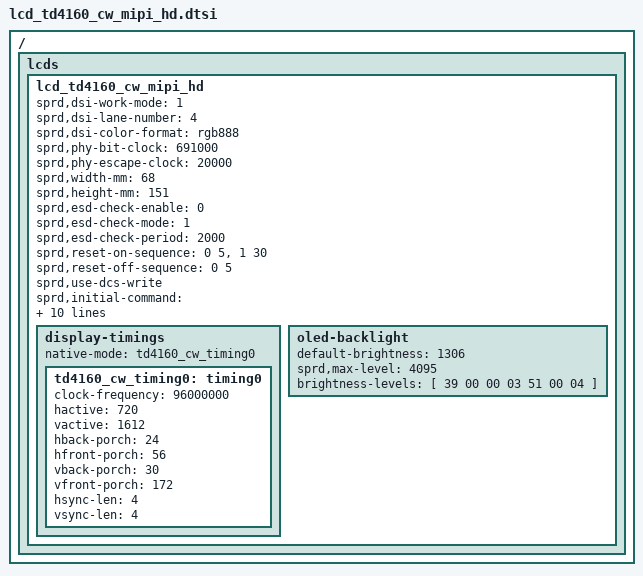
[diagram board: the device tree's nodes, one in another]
/*
 * R61350 Truly LCD config dtsi file for spreadtrum
 *
 * Copyright (C) 2018, Spreadtrum Communications Inc.
 *
 * SPDX-License-Identifier: (GPL-2.0+ OR MIT)
 */

/ {
	fragment {
		target-path = "/";
		__overlay__ {
			lcds {
				lcd_td4160_cw_mipi_hd: lcd_td4160_cw_mipi_hd {

					sprd,dsi-work-mode = <1>; /* video burst mode*/
					sprd,dsi-lane-number = <4>;
					sprd,dsi-color-format = "rgb888";

					sprd,phy-bit-clock = <691000>;	/* kbps */
					sprd,phy-escape-clock = <20000>;/* kHz */

					sprd,width-mm = <68>;
					sprd,height-mm = <151>;

					sprd,esd-check-enable = <0>;
					sprd,esd-check-mode = <1>;
					sprd,esd-check-period = <2000>;
					/* sprd,esd-check-register = <0x0A>; */
					/* sprd,esd-check-value = <0x9C>; */

					sprd,reset-on-sequence = <0 5>, <1 30>;
					sprd,reset-off-sequence = <0 5>;

					sprd,use-dcs-write;
					sprd,initial-command = [
		29 00 00 02 B0 00
		29 00 00 02 D6 00
		29 00 00 07 B6 30 62 00 86 C3 03 
		29 00 00 05 B7 31 00 00 00 
		29 00 00 07 B8 02 4A 06 00 04 5A 
		29 00 00 07 B9 02 4A 18 00 09 B4 
		29 00 00 07 BA 20 00 00 00 00 00 
		29 00 00 04 BB 00 B4 A0 
		29 00 00 04 BC 00 B4 A0 
		29 00 00 04 BD 00 B4 A0 
		29 00 00 0E BE 07 00 00 00 00 00 00 00 00 00 00 00 00 
		29 00 00 19 C0 00 80 18 06 4C 00 16 08 68 00 70 00 00 00 00 00 00 00 00 00 00 00 00 00 
		29 00 00 28 C1 30 41 50 FA 01 00 00 10 00 00 00 00 40 0F 00 00 00 00 00 00 00 00 00 00 00 00 00 00 00 00 00 00 00 00 00 00 00 00 00 
		29 00 00 F5 C2 00 00 50 14 06 10 0E 00 00 00 00 50 12 06 10 0A 00 00 00 00 50 12 06 06 69 00 00 00 00 00 00 00 00 00 00 00 00 00 00 00 00 00 05 D0 56 0C 0C 06 00 C1 00 B0 01 03 00 41 00 00 00 00 00 11 00 00 00 00 00 00 00 00 00 00 00 00 00 00 00 00 00 00 00 00 00 00 00 00 00 00 00 00 00 00 00 11 00 00 00 00 00 00 00 00 00 00 00 00 00 00 00 00 00 00 00 00 00 00 00 00 00 00 00 00 00 00 00 11 00 00 00 00 00 00 00 00 00 00 00 00 00 00 00 00 00 00 00 00 00 00 00 00 00 00 00 00 00 00 00 11 00 00 00 00 00 00 00 00 00 00 00 00 00 00 00 00 00 00 00 00 00 00 00 00 00 00 00 00 00 00 00 00 00 00 00 00 00 00 00 10 00 00 00 00 00 00 00 00 00 00 00 00 00 00 00 02 00 00 00 00 00 00 00 00 00 00 02 00 00 00 00 00 00 00 00 00 00 00 00 00 00 00 00 00 00 00 
		29 00 00 6A C3 00 00 50 01 67 10 05 00 00 00 20 00 04 E0 00 41 64 C0 02 00 00 00 20 00 00 00 00 00 00 00 00 00 00 00 20 00 00 00 00 00 00 00 00 00 00 00 20 00 00 00 00 08 00 00 00 00 00 00 00 00 00 00 00 00 00 00 00 00 00 00 00 00 00 00 00 00 00 00 00 00 00 00 00 00 00 00 00 00 00 00 00 00 00 00 00 00 00 00 00 00 00 00 00 00 00 
		29 00 00 55 C4 00 5F 5F 0C 5D 04 06 08 01 14 14 16 16 18 18 1A 1A 1C 1C 1E 1E 5F 00 00 5F 1D 1D 1B 1B 19 19 17 17 15 15 13 13 01 07 05 03 5D 0B 5F 5F 00 00 00 00 00 00 00 FF 0F FF 0F 00 00 00 00 00 00 00 00 00 00 00 00 00 33 33 00 00 55 55 55 55 55 41 55 55 55 55 55 
		29 00 00 06 C5 08 00 00 00 00 
		29 00 00 4D C6 00 00 00 00 01 22 04 22 01 00 53 00 00 00 01 00 53 00 01 05 01 0B 01 35 FF 8F 06 15 01 C0 07 00 00 00 00 00 00 00 00 00 00 00 00 00 00 00 00 00 00 00 00 00 00 20 20 00 00 00 C0 11 00 00 00 10 10 00 00 00 01 00 50 00 33 03 00 00 
		29 00 00 1F CB 02 D0 01 80 00 00 00 00 00 00 00 00 00 00 00 00 00 00 00 00 00 00 40 70 00 00 00 00 00 FF 
		29 00 00 19 CE 16 40 60 78 87 94 9E AB B8 C4 CD D6 DE E5 EC F3 FF 07 0F 00 00 00 04 8C 
		29 00 00 02 CF 00 
		29 00 00 15 D0 C1 50 81 66 09 90 00 CC 92 9F 11 1E 06 7E 09 08 CC 1B F0 06 
		29 00 00 26 D1 D0 D0 1B 33 33 17 07 BB 22 52 22 52 00 3B 77 07 3B 30 06 72 33 13 00 D7 0C 22 02 00 18 70 18 77 11 11 11 20 20
		29 00 00 04 D2 00 00 00 
		29 00 00 9A D3 00 00 00 00 00 00 00 00 00 FF F7 FF FF F7 FF FF F7 FF FF F7 FF FF F7 FF FF F7 FF FF F7 FF FF F7 FF FF F7 FF FF F7 FF FF F7 FF FF F7 FF FF F7 FF FF F7 FF FF F7 FF FF F7 FF FF F7 FF FF F7 FF FF F7 FF FF F7 FF FF F7 FF FF F7 FF FF F7 FF FF F7 FF FF F7 FF FF F7 FF FF F7 FF FF F7 FF FF F7 FF FF F7 FF FF F7 FF FF F7 FF FF F7 FF FF F7 FF FF F7 FF FF F7 FF FF F7 FF FF F7 FF FF F7 FF FF F7 FF FF F7 FF FF F7 FF FF F7 FF FF F7 FF FF F7 FF FF F7 FF FF F7 FF FF F7 FF 
		29 00 00 18 D4 00 00 00 00 00 00 00 00 00 20 00 00 00 00 20 00 00 00 00 00 00 00 00 
		29 00 00 2F D7 01 00 12 12 00 54 01 04 00 54 01 04 03 83 80 85 85 85 87 84 45 86 87 80 88 86 89 83 83 87 84 88 8A 0C 0B 0A 0A 0A 07 07 06 06 00 08 0A 0A 
		29 00 00 17 D8 40 99 26 ED 16 6C 16 6C 16 6C 00 14 00 14 00 14 01 0C 00 00 01 00 
		29 00 00 29 D9 00 02 7F 00 00 00 00 00 00 00 00 00 00 00 00 C0 00 00 00 00 00 00 00 00 00 00 00 00 00 00 00 00 00 00 00 00 00 00 00 00 
		29 00 00 05 DD 30 06 23 65 
		29 00 00 0F DE 00 00 00 0F FF 00 00 00 00 10 00 00 00 00 
		29 00 00 09 E6 00 00 00 00 00 00 00 00 
		29 00 00 24 EA 02 0E 0E 06 80 07 40 74 00 00 00 03 33 07 07 00 54 00 54 00 54 01 28 01 28 00 54 00 54 00 54 00 08 02 00 
		29 00 00 09 EB 08 30 83 0B 41 01 08 00 
		29 00 00 18 EC 05 F0 01 70 6B 07 40 74 00 00 00 02 2A 00 00 00 00 00 00 00 00 00 00 
		29 00 00 22 ED 01 02 00 00 00 00 00 00 67 C6 FE 00 00 00 00 00 00 00 00 00 00 00 02 B0 00 00 00 00 00 00 C0 10 00 
		29 00 00 7A EE 05 00 01 00 C0 57 00 C0 57 00 C0 57 00 00 03 00 C0 57 00 00 00 00 00 00 03 00 00 00 00 00 00 03 00 00 00 00 00 00 03 00 00 00 00 00 00 03 00 C0 57 00 00 00 00 00 C0 0F 00 00 00 00 00 00 57 00 00 00 00 00 00 03 00 00 00 00 00 00 03 00 00 03 00 00 03 00 00 03 00 00 03 00 00 03 00 00 03 00 00 00 00 00 00 00 00 00 00 00 00 00 00 00 00 00 00 00 00 00 00 00 00 00 02 
		29 00 00 0C F9 20 3F E0 00 00 07 FF 00 00 07 FF 
		29 00 00 4D C7 00 00 00 55 00 C2 01 0F 01 82 01 B5 01 B5 01 BA 01 B2 01 B1 01 AD 01 A7 01 A3 01 8C 01 99 02 2C 02 6F 02 9D 02 FF 00 00 00 55 00 C2 01 0F 01 82 01 B5 01 B5 01 BA 01 B2 01 B1 01 AD 01 A7 01 A3 01 8C 01 99 02 2C 02 6F 02 9D 02 FF 
		29 00 00 03 51 03 FF 
		29 00 00 02 53 2C 
		29 00 00 02 55 00 
		29 00 00 02 B0 03 
		05 60 00 01 11 
		05 20 00 01 29
						];

					sprd,sleep-in-command = [
						05 14 00 01 28
						05 78 00 01 10
						];

					sprd,sleep-out-command = [
						05 14 00 01 11
						05 78 00 01 29
						];

					sprd,cabc-off-command = [
						23 00 00 02 55 00
						];
					sprd,cabc-ui-command = [
						23 00 00 02 55 01
						];
					sprd,cabc-still-command = [
						23 00 00 02 55 02
						];
					sprd,cabc-moving-command = [
						23 00 00 02 55 03
						];


					display-timings {
						native-mode = <&td4160_cw_timing0>;

						td4160_cw_timing0: timing0 {
							clock-frequency = <96000000>;
							hactive = <720>;
							vactive = <1612>;
							hback-porch = <24>;
							hfront-porch = <56>;
							vback-porch = <30>;
							vfront-porch = <172>;
							hsync-len = <4>;
							vsync-len = <4>;
						};
					};

					oled-backlight {
						default-brightness = <1306>;
						sprd,max-level = <4095>;
						brightness-levels = [
            		    	39 00 00 03 51 00 04
						];
					};
				};
			};
		};
	};
};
